# STM32G474xx register map
File version: 1.5
CPU: CM4 r0p1, little endian, MPU, FPU, 4 interrupt priority bits
Registers are 32-bit, read-write, reset 0x0 unless marked. A register's access mark holds for its fields unless they carry their own. Offsets are from the block's base; [hi:lo] are bit positions; {n}, {i} and the like mark numbered series; 'fields as' and 'values as' point back to an identical list.

## HRTIM_TIMC — High Resolution Timer: TIMC
Base 0x40016980
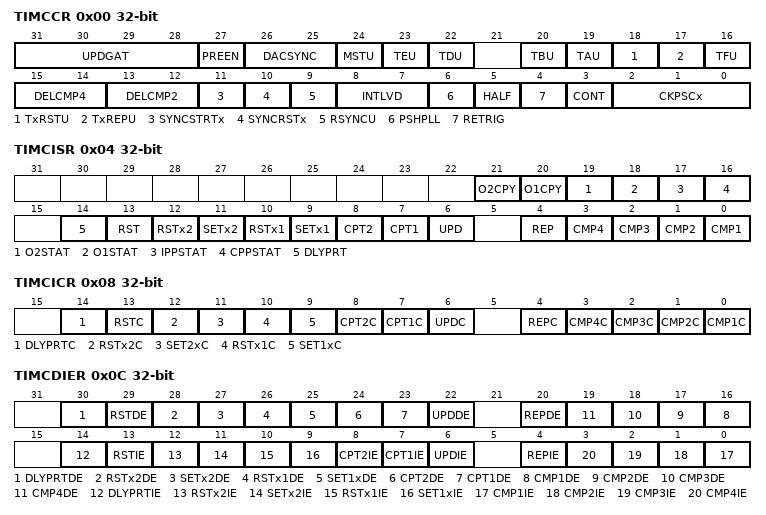
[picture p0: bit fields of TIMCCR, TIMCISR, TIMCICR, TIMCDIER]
0x00 TIMCCR — Timerx Control Register
  [31:28] UPDGAT — Update Gating
  [27] PREEN — Preload enable
  [26:25] DACSYNC — AC Synchronization
  [24] MSTU — Master Timer update
  [23] TEU
  [22] TDU
  [20] TBU
  [19] TAU
  [18] TxRSTU — Timerx reset update
  [17] TxREPU — Timer x Repetition update
  [16] TFU
  [15:14] DELCMP4 — Delayed CMP4 mode
  [13:12] DELCMP2 — Delayed CMP2 mode
  [11] SYNCSTRTx — Synchronization Starts Timer x
  [10] SYNCRSTx — Synchronization Resets Timer x
  [9] RSYNCU — Re-Synchronized Update
  [8:7] INTLVD — Interleaved mode
  [6] PSHPLL — Push-Pull mode enable
  [5] HALF — Half mode enable
  [4] RETRIG — Re-triggerable mode
  [3] CONT — Continuous mode
  [2:0] CKPSCx — HRTIM Timer x Clock prescaler
0x04 TIMCISR ro — Timerx Interrupt Status Register
  [21] O2CPY — Output 2 Copy
  [20] O1CPY — Output 1 Copy
  [19] O2STAT — Output 2 State
  [18] O1STAT — Output 1 State
  [17] IPPSTAT — Idle Push Pull Status
  [16] CPPSTAT — Current Push Pull Status
  [14] DLYPRT — Delayed Protection Flag
  [13] RST — Reset Interrupt Flag
  [12] RSTx2 — Output 2 Reset Interrupt Flag
  [11] SETx2 — Output 2 Set Interrupt Flag
  [10] RSTx1 — Output 1 Reset Interrupt Flag
  [9] SETx1 — Output 1 Set Interrupt Flag
  [8] CPT2 — Capture2 Interrupt Flag
  [7] CPT1 — Capture1 Interrupt Flag
  [6] UPD — Update Interrupt Flag
  [4] REP — Repetition Interrupt Flag
  [n-1] CMP{n} (n=1..4) — Compare {n} Interrupt Flag
0x08 TIMCICR wo — Timerx Interrupt Clear Register
  [14] DLYPRTC — Delayed Protection Flag Clear
  [13] RSTC — Reset Interrupt flag Clear
  [12] RSTx2C — Output 2 Reset flag Clear
  [11] SET2xC — Output 2 Set flag Clear
  [10] RSTx1C — Output 1 Reset flag Clear
  [9] SET1xC — Output 1 Set flag Clear
  [8] CPT2C — Capture2 Interrupt flag Clear
  [7] CPT1C — Capture1 Interrupt flag Clear
  [6] UPDC — Update Interrupt flag Clear
  [4] REPC — Repetition Interrupt flag Clear
  [n-1] CMP{n}C (n=1..4) — Compare {n} Interrupt flag Clear
0x0C TIMCDIER — TIMxDIER
  [30] DLYPRTDE, [29] RSTDE, [28] RSTx2DE, [27] SETx2DE, [26] RSTx1DE, [25] SET1xDE, [24] CPT2DE, [23] CPT1DE, [22] UPDDE, [20] REPDE, [n+15] CMP{n}DE (n=1..4), [14] DLYPRTIE, [13] RSTIE, [12] RSTx2IE, [11] SETx2IE, [10] RSTx1IE, [9] SET1xIE, [8] CPT2IE, [7] CPT1IE, [6] UPDIE, [4] REPIE, [n-1] CMP{n}IE (n=1..4)
0x10 CNTCR — Timerx Counter Register
  [15:0] CNTx — Timerx Counter value
0x14 PERCR reset 0xFFFF — Timerx Period Register
  [15:0] PERx — Timerx Period value
0x18 REPCR — Timerx Repetition Register
  [7:0] REPx — Timerx Repetition counter value
0x1C CMP1CR — Timerx Compare 1 Register
  [15:0] CMP1x — Timerx Compare 1 value
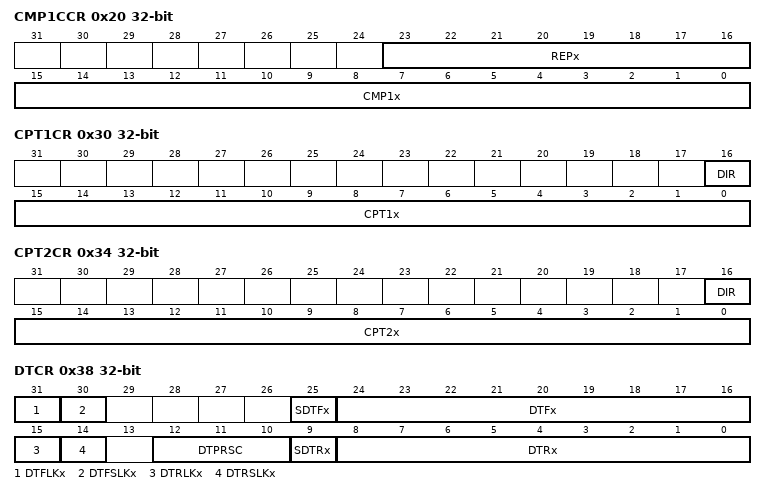
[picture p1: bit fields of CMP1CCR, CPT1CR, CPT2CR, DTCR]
0x20 CMP1CCR — Timerx Compare 1 Compound Register
  [23:16] REPx — Timerx Repetition value (aliased from HRTIM_REPx register)
  [15:0] CMP1x — Timerx Compare 1 value
{0x1C+4i} CMP{i}CR (i=2..4) — Timerx Compare {i} Register
  [15:0] CMP{i}x — Timerx Compare {i} value
0x30 CPT1CR ro — Timerx Capture 1 Register
  [16] DIR — Timerx Capture 1 Direction status
  [15:0] CPT1x — Timerx Capture 1 value
0x34 CPT2CR ro — Timerx Capture 2 Register
  [16] DIR — Timerx Capture 1 Direction status
  [15:0] CPT2x — Timerx Capture 2 value
0x38 DTCR — Timerx Deadtime Register
  [31] DTFLKx — Deadtime Falling Lock
  [30] DTFSLKx — Deadtime Falling Sign Lock
  [25] SDTFx — Sign Deadtime Falling value
  [24:16] DTFx — Deadtime Falling value
  [15] DTRLKx — Deadtime Rising Lock
  [14] DTRSLKx — Deadtime Rising Sign Lock
  [12:10] DTPRSC — Deadtime Prescaler
  [9] SDTRx — Sign Deadtime Rising value
  [8:0] DTRx — Deadtime Rising value
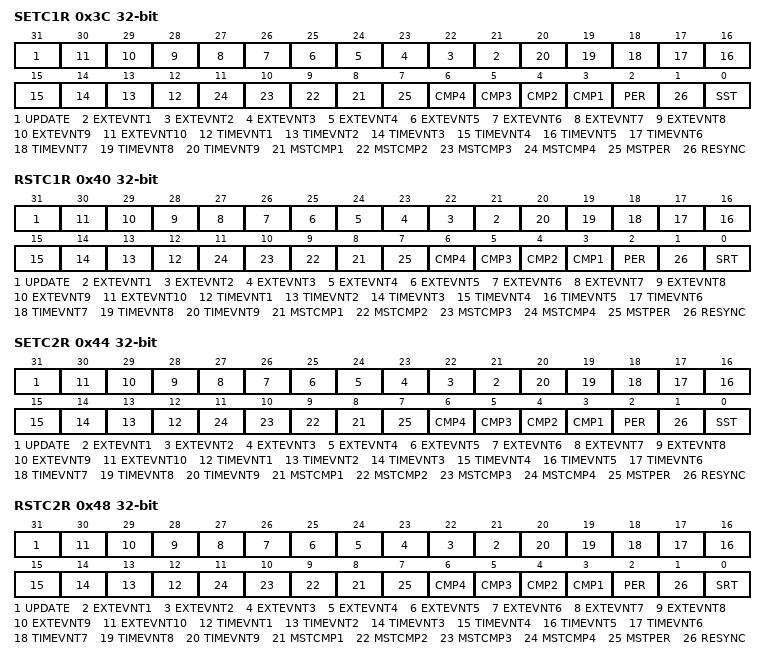
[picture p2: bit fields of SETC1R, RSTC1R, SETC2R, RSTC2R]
0x3C SETC1R — Timerx Output1 Set Register
  [31] UPDATE — Registers update (transfer preload to active)
  [n+20] EXTEVNT{n} (n=1..10) — External Event {n}
  [n+11] TIMEVNT{n} (n=1..9) — Timer Event {n}
  [n+7] MSTCMP{n} (n=1..4) — Master Compare {n}
  [7] MSTPER — Master Period
  [n+2] CMP{n} (n=1..4) — Timer A compare {n}
  [2] PER — Timer A Period
  [1] RESYNC — Timer A resynchronizaton
  [0] SST — Software Set trigger
0x40 RSTC1R — Timerx Output1 Reset Register
  [31] UPDATE, [n+20] EXTEVNT{n} (n=1..10), [n+11] TIMEVNT{n} (n=1..9), [n+7] MSTCMP{n} (n=1..4), [7] MSTPER, [n+2] CMP{n} (n=1..4), [2] PER, [1] RESYNC, [0] SRT
0x44 SETC2R — Timerx Output2 Set Register
  [31] UPDATE, [n+20] EXTEVNT{n} (n=1..10), [n+11] TIMEVNT{n} (n=1..9), [n+7] MSTCMP{n} (n=1..4), [7] MSTPER, [n+2] CMP{n} (n=1..4), [2] PER, [1] RESYNC, [0] SST
0x48 RSTC2R — Timerx Output2 Reset Register
  fields as RSTC1R
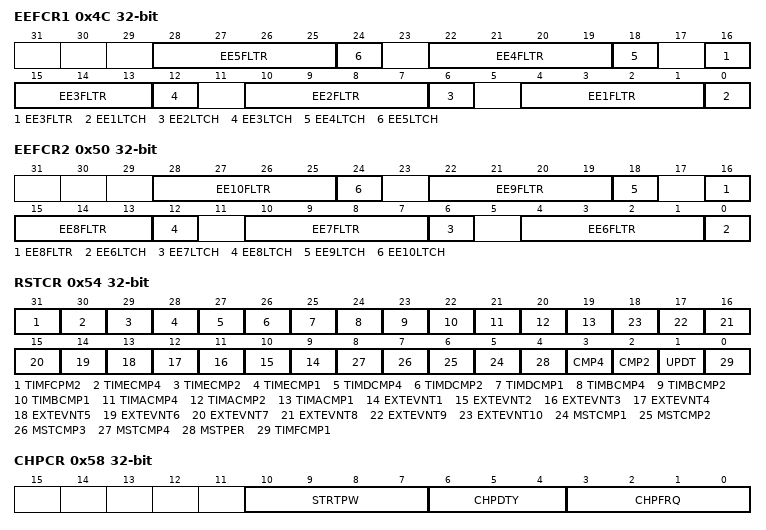
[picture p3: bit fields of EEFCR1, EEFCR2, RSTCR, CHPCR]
0x4C EEFCR1 — Timerx External Event Filtering Register 1
  [6n-2:6n-5] EE{n}FLTR (n=1..5) — External Event {n} filter
  [6n-6] EE{n}LTCH (n=1..5) — External Event {n} latch
0x50 EEFCR2 — Timerx External Event Filtering Register 2
  [6n-32:6n-35] EE{n}FLTR (n=6..10) — External Event {n} filter
  [6n-36] EE{n}LTCH (n=6..10) — External Event {n} latch
0x54 RSTCR — TimerA Reset Register
  [31] TIMFCPM2 — Timer F Compare 2
  [30] TIMECMP4 — Timer E Compare 4
  [29] TIMECMP2 — Timer E Compare 2
  [28] TIMECMP1 — Timer E Compare 1
  [27] TIMDCMP4 — Timer D Compare 4
  [26] TIMDCMP2 — Timer D Compare 2
  [25] TIMDCMP1 — Timer D Compare 1
  [24] TIMBCMP4 — Timer B Compare 4
  [23] TIMBCMP2 — Timer B Compare 2
  [22] TIMBCMP1 — Timer B Compare 1
  [21] TIMACMP4 — Timer A Compare 4
  [20] TIMACMP2 — Timer A Compare 2
  [19] TIMACMP1 — Timer A Compare 1
  [n+8] EXTEVNT{n} (n=1..10) — External Event {n}
  [n+4] MSTCMP{n} (n=1..4) — Master compare {n}
  [4] MSTPER — Master timer Period
  [3] CMP4 — Timer A compare 4 reset
  [2] CMP2 — Timer A compare 2 reset
  [1] UPDT — Timer A Update reset
  [0] TIMFCMP1 — Timer A Update reset
0x58 CHPCR — Timerx Chopper Register
  [10:7] STRTPW
  [6:4] CHPDTY — Timerx chopper duty cycle value
  [3:0] CHPFRQ — Timerx carrier frequency value
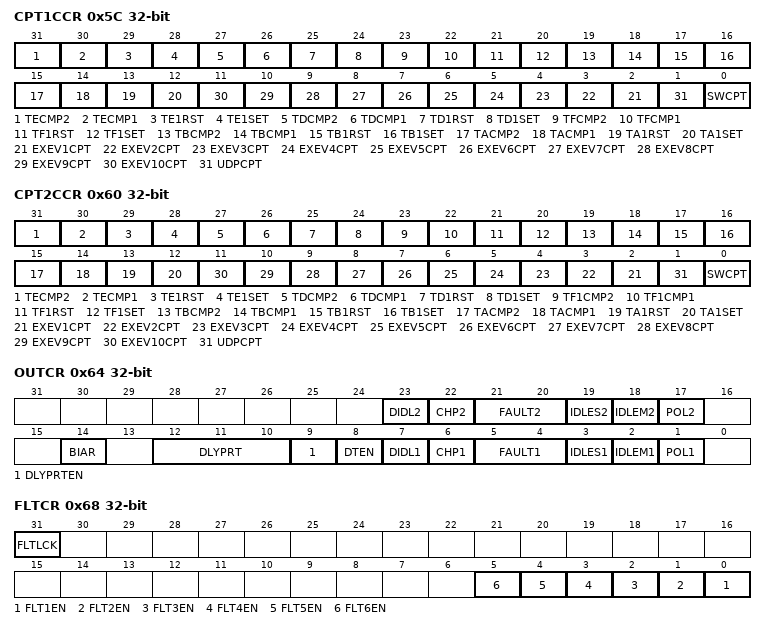
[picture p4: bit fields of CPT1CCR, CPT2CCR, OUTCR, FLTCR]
0x5C CPT1CCR — Timerx Capture 1 Control Register
  [31] TECMP2 — Timer E Compare 2
  [30] TECMP1 — Timer E Compare 1
  [29] TE1RST — Timer E output 1 Reset
  [28] TE1SET — Timer E output 1 Set
  [27] TDCMP2 — Timer D Compare 2
  [26] TDCMP1 — Timer D Compare 1
  [25] TD1RST — Timer D output 1 Reset
  [24] TD1SET — Timer D output 1 Set
  [23] TFCMP2
  [22] TFCMP1
  [21] TF1RST
  [20] TF1SET
  [19] TBCMP2 — Timer B Compare 2
  [18] TBCMP1 — Timer B Compare 1
  [17] TB1RST — Timer B output 1 Reset
  [16] TB1SET — Timer B output 1 Set
  [15] TACMP2 — Timer A Compare 2
  [14] TACMP1 — Timer A Compare 1
  [13] TA1RST — Timer A output 1 Reset
  [12] TA1SET — Timer A output 1 Set
  [n+1] EXEV{n}CPT (n=1..10) — External Event {n} Capture
  [1] UDPCPT — Update Capture
  [0] SWCPT — Software Capture
0x60 CPT2CCR — Timerx Capture 2 Control Register
  [31] TECMP2 — Timer E Compare 2
  [30] TECMP1 — Timer E Compare 1
  [29] TE1RST — Timer E output 1 Reset
  [28] TE1SET — Timer E output 1 Set
  [27] TDCMP2 — Timer D Compare 2
  [26] TDCMP1 — Timer D Compare 1
  [25] TD1RST — Timer D output 1 Reset
  [24] TD1SET — Timer D output 1 Set
  [23] TF1CMP2
  [22] TF1CMP1
  [21] TF1RST
  [20] TF1SET
  [19] TBCMP2 — Timer B Compare 2
  [18] TBCMP1 — Timer B Compare 1
  [17] TB1RST — Timer B output 1 Reset
  [16] TB1SET — Timer B output 1 Set
  [15] TACMP2 — Timer A Compare 2
  [14] TACMP1 — Timer A Compare 1
  [13] TA1RST — Timer A output 1 Reset
  [12] TA1SET — Timer A output 1 Set
  [n+1] EXEV{n}CPT (n=1..10) — External Event {n} Capture
  [1] UDPCPT — Update Capture
  [0] SWCPT — Software Capture
0x64 OUTCR — Timerx Output Register
  [23] DIDL2 — Output 2 Deadtime upon burst mode Idle entry
  [22] CHP2 — Output 2 Chopper enable
  [21:20] FAULT2 — Output 2 Fault state
  [19] IDLES2 — Output 2 Idle State
  [18] IDLEM2 — Output 2 Idle mode
  [17] POL2 — Output 2 polarity
  [14] BIAR — Balanced Idle Automatic Resume
  [12:10] DLYPRT — Delayed Protection
  [9] DLYPRTEN — Delayed Protection Enable
  [8] DTEN — Deadtime enable
  [7] DIDL1 — Output 1 Deadtime upon burst mode Idle entry
  [6] CHP1 — Output 1 Chopper enable
  [5:4] FAULT1 — Output 1 Fault state
  [3] IDLES1 — Output 1 Idle State
  [2] IDLEM1 — Output 1 Idle mode
  [1] POL1 — Output 1 polarity
0x68 FLTCR — Timerx Fault Register
  [31] FLTLCK — Fault sources Lock
  [n-1] FLT{n}EN (n=1..6) — Fault {n} enable
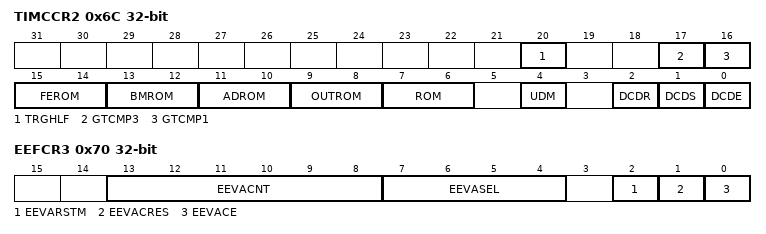
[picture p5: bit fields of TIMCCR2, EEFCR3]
0x6C TIMCCR2 — HRTIM Timerx Control Register 2
  [20] TRGHLF — Triggered-half mode
  [17] GTCMP3 — Greater than Compare 3 PWM mode
  [16] GTCMP1 — Greater than Compare 1 PWM mode
  [15:14] FEROM — Fault and Event Roll-Over Mode
  [13:12] BMROM — Burst Mode Roll-Over Mode
  [11:10] ADROM — ADC Roll-Over Mode
  [9:8] OUTROM — Output Roll-Over Mode
  [7:6] ROM — Roll-Over Mode
  [4] UDM — Up-Down Mode
  [2] DCDR — Dual Channel DAC Reset trigger
  [1] DCDS — Dual Channel DAC Step trigger
  [0] DCDE — Dual Channel DAC trigger enable
0x70 EEFCR3 — HRTIM Timerx External Event Filtering Register 3
  [13:8] EEVACNT — External Event A counter
  [7:4] EEVASEL — External Event A Selection
  [2] EEVARSTM — External Event A Reset Mode
  [1] EEVACRES — External Event A Counter Reset
  [0] EEVACE — External Event A Counter Enable
